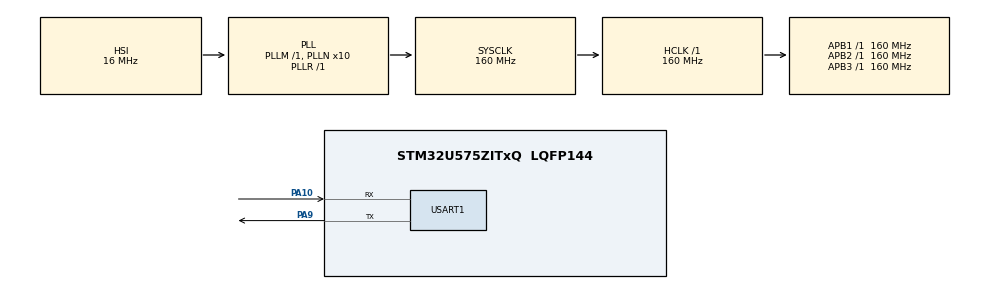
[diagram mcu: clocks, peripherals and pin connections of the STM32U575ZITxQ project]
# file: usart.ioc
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CORTEX_M33_NS.userName=CORTEX_M33
GPDMA1.CIRCULARMODE_GPDMACH10=ENABLE
GPDMA1.IPHANDLE_GPDMACH10-SIMPLEREQUEST_GPDMACH10=__NULL
GPDMA1.IPHANDLE_GPDMACH11-SIMPLEREQUEST_GPDMACH11=__NULL
GPDMA1.LINKALLOCATEDPORT_CIRCULAR_GPDMACH10=DMA_LINK_ALLOCATED_PORT1
GPDMA1.REQUEST_GPDMACH10=GPDMA1_REQUEST_USART1_RX
GPDMA1.REQUEST_GPDMACH11=GPDMA1_REQUEST_USART1_TX
GPDMA1.TRANSFERALLOCATEDPORTDEST_GPDMACH10=DMA_DEST_ALLOCATED_PORT1
GPDMA1.TRANSFERALLOCATEDPORTSRC_GPDMACH10=DMA_SRC_ALLOCATED_PORT1
Mcu.Family=STM32U5
Mcu.Name=STM32U575ZITxQ
Mcu.Package=LQFP144
NVIC.GPDMA1_Channel10_IRQn=true\:0\:0\:false\:false\:true\:false\:true\:true
NVIC.GPDMA1_Channel11_IRQn=true\:0\:0\:false\:false\:true\:false\:true\:true
NVIC.PriorityGroup=NVIC_PRIORITYGROUP_3
PA10.Mode=Asynchronous
PA10.Signal=USART1_RX
PA9.Mode=Asynchronous
PA9.Signal=USART1_TX
PH0-OSC_IN\ (PH0).Mode=HSE-External-Oscillator
PH0-OSC_IN\ (PH0).Signal=RCC_OSC_IN
PH1-OSC_OUT\ (PH1).Mode=HSE-External-Oscillator
PH1-OSC_OUT\ (PH1).Signal=RCC_OSC_OUT
ProjectManager.HeapSize=0x200
ProjectManager.StackSize=0x400
ProjectManager.TargetToolchain=STM32CubeIDE
RCC.ADCFreq_Value=16000000
RCC.AHBFreq_Value=160000000
RCC.APB1Freq_Value=160000000
RCC.APB1TimFreq_Value=160000000
RCC.APB2Freq_Value=160000000
RCC.APB2TimFreq_Value=160000000
RCC.APB3Freq_Value=160000000
RCC.CortexFreq_Value=160000000
RCC.DACCLockSelectionVirtual=RCC_DAC1CLKSOURCE_LSI
RCC.EPOD_VALUE=16000000
RCC.HCLKFreq_Value=160000000
RCC.HSE_VALUE=16000000
RCC.HSI48_VALUE=48000000
RCC.HSI_VALUE=16000000
RCC.LSE_VALUE=32768
RCC.LSIDIV_VALUE=32000
RCC.MSIClockRange=RCC_MSIRANGE_0
RCC.MSI_VALUE=48000000
RCC.PLL1R=1
RCC.PLLFRACN=0
RCC.PLLN=10
RCC.PLLSourceVirtual=RCC_PLLSOURCE_HSI
RCC.SYSCLKFreq_VALUE=160000000
RCC.SYSCLKSource=RCC_SYSCLKSOURCE_PLLCLK
RCC.USBFreq_Value=48000000
RCC.VCOOutputFreq_Value=160000000
USART1.VirtualMode-Asynchronous=VM_ASYNC
VP_GPDMA1_VS_GPDMACH10.Mode=SIMPLEREQUEST_GPDMACH10
VP_GPDMA1_VS_GPDMACH11.Mode=SIMPLEREQUEST_GPDMACH11
VP_ICACHE_VS_ICACHE.Mode=DefaultMode
VP_LPBAMQUEUE_VS_QUEUE.Mode=QUEUEMODE
VP_LPBAM_VS_SIG1.Mode=SmartRun
VP_LPBAM_VS_SIG4.Mode=LPDMA1
VP_MEMORYMAP_VS_MEMORYMAP.Mode=CurAppReg
VP_PWR_VS_SECSignals.Mode=Security/Privilege
board=NUCLEO-U575ZI-Q

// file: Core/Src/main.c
/* USER CODE BEGIN Header */
/**
 ******************************************************************************
 * @file           : main.c
 * @brief          : Main program body
 ******************************************************************************
 * @attention
 *
 * Copyright (c) 2024 STMicroelectronics.
 * All rights reserved.
 *
 * This software is licensed under terms that can be found in the LICENSE file
 * in the root directory of this software component.
 * If no LICENSE file comes with this software, it is provided AS-IS.
 *
 ******************************************************************************
 */
/* USER CODE END Header */
#include "main.h"

UART_HandleTypeDef huart1;
DMA_HandleTypeDef handle_GPDMA1_Channel11;
DMA_NodeTypeDef Node_GPDMA1_Channel10;
DMA_QListTypeDef List_GPDMA1_Channel10;
DMA_HandleTypeDef handle_GPDMA1_Channel10;

/* USER CODE BEGIN PV */
int const SIZE = 64;
uint8_t rxBuf[64];
uint8_t txBuf[64] = { "Count:  \r\n" };
/* USER CODE END PV */

void SystemClock_Config(void);
static void MX_GPIO_Init(void);
static void MX_GPDMA1_Init(void);
static void MX_USART1_UART_Init(void);
static void MX_ICACHE_Init(void);

int main(void)
{

  /* MCU Configuration--------------------------------------------------------*/

  /* Reset of all peripherals, Initializes the Flash interface and the Systick. */
  HAL_Init();

  /* Configure the system clock */
  SystemClock_Config();

  /* Initialize all configured peripherals */
  MX_GPIO_Init();
  MX_GPDMA1_Init();
  MX_USART1_UART_Init();
  MX_ICACHE_Init();
  /* USER CODE BEGIN 2 */

	HAL_UART_Receive_DMA(&huart1, rxBuf, SIZE);
	uint8_t counter = 0x30;

  /* USER CODE END 2 */

  /* Infinite loop */
  /* USER CODE BEGIN WHILE */
	while (1) {
		txBuf[7] = counter++;
		if (counter > 0x39) {
			counter = 0x30;
		}

		HAL_UART_Transmit_DMA(&huart1, txBuf, SIZE);

		HAL_Delay(1000);

    /* USER CODE END WHILE */

	}
}

void SystemClock_Config(void)
{
  RCC_OscInitTypeDef RCC_OscInitStruct = {0};
  RCC_ClkInitTypeDef RCC_ClkInitStruct = {0};

  /** Configure the main internal regulator output voltage
  */
  if (HAL_PWREx_ControlVoltageScaling(PWR_REGULATOR_VOLTAGE_SCALE1) != HAL_OK)
  {
    Error_Handler();
  }

  /** Initializes the CPU, AHB and APB buses clocks
  */
  RCC_OscInitStruct.OscillatorType = RCC_OSCILLATORTYPE_HSI;
  RCC_OscInitStruct.HSIState = RCC_HSI_ON;
  RCC_OscInitStruct.HSICalibrationValue = RCC_HSICALIBRATION_DEFAULT;
  RCC_OscInitStruct.PLL.PLLState = RCC_PLL_ON;
  RCC_OscInitStruct.PLL.PLLSource = RCC_PLLSOURCE_HSI;
  RCC_OscInitStruct.PLL.PLLMBOOST = RCC_PLLMBOOST_DIV1;
  RCC_OscInitStruct.PLL.PLLM = 1;
  RCC_OscInitStruct.PLL.PLLN = 10;
  RCC_OscInitStruct.PLL.PLLP = 2;
  RCC_OscInitStruct.PLL.PLLQ = 2;
  RCC_OscInitStruct.PLL.PLLR = 1;
  RCC_OscInitStruct.PLL.PLLRGE = RCC_PLLVCIRANGE_1;
  RCC_OscInitStruct.PLL.PLLFRACN = 0;
  if (HAL_RCC_OscConfig(&RCC_OscInitStruct) != HAL_OK)
  {
    Error_Handler();
  }

  /** Initializes the CPU, AHB and APB buses clocks
  */
  RCC_ClkInitStruct.ClockType = RCC_CLOCKTYPE_HCLK|RCC_CLOCKTYPE_SYSCLK
                              |RCC_CLOCKTYPE_PCLK1|RCC_CLOCKTYPE_PCLK2
                              |RCC_CLOCKTYPE_PCLK3;
  RCC_ClkInitStruct.SYSCLKSource = RCC_SYSCLKSOURCE_PLLCLK;
  RCC_ClkInitStruct.AHBCLKDivider = RCC_SYSCLK_DIV1;
  RCC_ClkInitStruct.APB1CLKDivider = RCC_HCLK_DIV1;
  RCC_ClkInitStruct.APB2CLKDivider = RCC_HCLK_DIV1;
  RCC_ClkInitStruct.APB3CLKDivider = RCC_HCLK_DIV1;

  if (HAL_RCC_ClockConfig(&RCC_ClkInitStruct, FLASH_LATENCY_4) != HAL_OK)
  {
    Error_Handler();
  }
}

static void MX_GPDMA1_Init(void)
{

  /* Peripheral clock enable */
  __HAL_RCC_GPDMA1_CLK_ENABLE();

  /* GPDMA1 interrupt Init */
    HAL_NVIC_SetPriority(GPDMA1_Channel10_IRQn, 0, 0);
    HAL_NVIC_EnableIRQ(GPDMA1_Channel10_IRQn);
    HAL_NVIC_SetPriority(GPDMA1_Channel11_IRQn, 0, 0);
    HAL_NVIC_EnableIRQ(GPDMA1_Channel11_IRQn);

}

static void MX_ICACHE_Init(void)
{

  /** Enable instruction cache (default 2-ways set associative cache)
  */
  if (HAL_ICACHE_Enable() != HAL_OK)
  {
    Error_Handler();
  }

}

static void MX_USART1_UART_Init(void)
{

  huart1.Instance = USART1;
  huart1.Init.BaudRate = 115200;
  huart1.Init.WordLength = UART_WORDLENGTH_8B;
  huart1.Init.StopBits = UART_STOPBITS_1;
  huart1.Init.Parity = UART_PARITY_NONE;
  huart1.Init.Mode = UART_MODE_TX_RX;
  huart1.Init.HwFlowCtl = UART_HWCONTROL_NONE;
  huart1.Init.OverSampling = UART_OVERSAMPLING_16;
  huart1.Init.OneBitSampling = UART_ONE_BIT_SAMPLE_DISABLE;
  huart1.Init.ClockPrescaler = UART_PRESCALER_DIV1;
  huart1.AdvancedInit.AdvFeatureInit = UART_ADVFEATURE_NO_INIT;
  if (HAL_UART_Init(&huart1) != HAL_OK)
  {
    Error_Handler();
  }
  if (HAL_UARTEx_SetTxFifoThreshold(&huart1, UART_TXFIFO_THRESHOLD_1_8) != HAL_OK)
  {
    Error_Handler();
  }
  if (HAL_UARTEx_SetRxFifoThreshold(&huart1, UART_RXFIFO_THRESHOLD_1_8) != HAL_OK)
  {
    Error_Handler();
  }
  if (HAL_UARTEx_DisableFifoMode(&huart1) != HAL_OK)
  {
    Error_Handler();
  }

}

static void MX_GPIO_Init(void)
{

  /* GPIO Ports Clock Enable */
  __HAL_RCC_GPIOH_CLK_ENABLE();
  __HAL_RCC_GPIOA_CLK_ENABLE();

}

/* USER CODE BEGIN 4 */
void HAL_UART_Rx_CpltCallback(UART_HandleTypeDef *huart) {
	HAL_UART_Transmit_DMA(&huart1, (uint8_t*)"Message received\r\n", sizeof("Message received\r\n"));
	HAL_UARTEx_ReceiveToIdle_DMA(&huart1, rxBuf, SIZE);
}
/* USER CODE END 4 */

void Error_Handler(void)
{
	__disable_irq();
	while (1) {
	}
}
